# MSPM0L222X register map
Vendor: Texas Instruments; File version: This preliminary header file does not have a version number - build date: 2024-04-29 20:57:13
ARM Device
CPU: CM0 r0p1, little endian, MPU, no FPU, 3 interrupt priority bits
Registers are 32-bit, read-write, reset 0x0 unless marked. A register's access mark holds for its fields unless they carry their own. Offsets are from the block's base; lines under a group give offsets from that group; [hi:lo] are bit positions; {n}, {i} and the like mark numbered series; 'fields as' and 'values as' point back to an identical list; <NAME> marks a mode.

## Memory map
0x00000000 FLASH size 0x40000 — MEM
0x20000000 SYSMEM size 0x8000 — MEM
0x40080000 WWDT0 size 0x1500 — WWDT
0x400A0000 GPIOA size 0x1F00 — PERIPHERALREGION
0x400A2000 GPIOB size 0x1F00 — PERIPHERALREGION
0x400A4000 GPIOC size 0x1F00 — PERIPHERALREGION
0x400AC000 KEYSTORECTL size 0x2000 — PERIPHERALREGION
0x400AF000 SYSCTL size 0x3100 — mem_map
0x400C7000 DEBUGSS size 0x1F00 — DSSM
0x400C9000 EVENTLP size 0x3000 — PERIPHERALREGION
0x400CD000 FLASHCTL size 0x2000 — NVMNW_GANDALF
0x400F0000 I2C0 size 0x1F00 — PERIPHERALREGION
0x400F2000 I2C1 size 0x1F00 — PERIPHERALREGION
0x400F4000 I2C2 size 0x1F00 — PERIPHERALREGION
0x40108000 UART0 size 0x1F00 — PERIPHERALREGION
0x4010A000 UART1 size 0x1F00 — PERIPHERALREGION
0x40400000 CPUSS size 0x1F00 — CPUSSMMR
0x40428000 IOMUX size 0x2000 — PERIPHERALREGION
0x4042A000 DMA size 0x1F00 — PERIPHERALREGION
0x40440000 CRCP0 size 0x2000 — PERIPHERALREGION
0x40442000 AESADV size 0x1200 — PERIPHERALREGION
0x40444000 TRNG size 0x1E00 — PERIPHERALREGION
0x40468000 SPI0 size 0x1F00 — PERIPHERALREGION
0x41C40000 FACTORYREGION size 0x80

## Interrupts
0 INT_GROUP0 (DEBUGSS, WWDT0, FLASHCTL, SYSCTL) — DEBUGSS interrupt (group 0, IIDX 2)
1 INT_GROUP1 (GPIOA, TRNG, GPIOB, GPIOC) — GPIOA interrupt (group 1, IIDX 0)
15 UART0
16 UART1
28 AESADV
31 DMA0 (DMA)

## FACTORYREGION
Base 0x41C40000
0x00 TRACEID ro — Unique value per device shipped
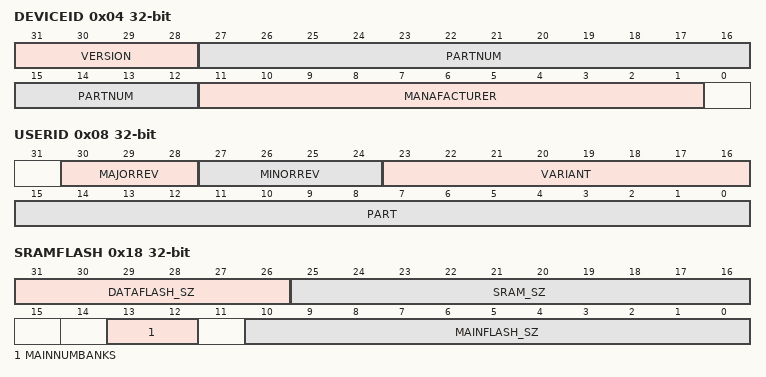
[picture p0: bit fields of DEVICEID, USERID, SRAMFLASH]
0x04 DEVICEID ro — Device Identifier
  [31:28] VERSION — Revision of this device
  [27:12] PARTNUM — Part number of the device
  [11:1] MANAFACTURER — TI's JEDEC bank and company code
0x08 USERID ro
  [30:28] MAJORREV — Monotonic increasing value indiciating a new revision of the SKU significant enough that users of the device may have tro revise PCB or software design
  [27:24] MINORREV — Monotonic increasing value indicating a new revision of the SKU that preserves compatability with lesser minor rev values. New capability may be introduced such that lesser minor rev numbers may not be compatible with greater if the new capability is used.
  [23:16] VARIANT — Bit pattern uniquely identifying the variant for the part
  [15:0] PART — Bit pattern that uniquely identifying a part
0x18 SRAMFLASH ro
  [31:26] DATAFLASH_SZ — The encoding of the field is that the value of the field is an integer to be interpreted as number of KB. For example id 4, then it is 4KB, if the value is 32, then 32KB, and so on.
  [25:16] SRAM_SZ — The encoding of the field is that the value of the field is an integer to be interpreted as number of KB. For example id 4, then it is 4KB, if the value is 32, then 32KB, and so on.
  [13:12] MAINNUMBANKS
  [10:0] MAINFLASH_SZ — The encoding of the field is that value of the field is an interger to be interpreted as number of KB. For example, if the value of the field id 4, then it is 4KB, the value is 32KB, and so on.

## Licence text in the file
Copyright (C) 2024 Texas Instruments Incorporated - http://www.ti.com/ Redistribution and use in source and binary forms, with or without modification, are permitted provided that the following conditions are met: Redistributions of source code must retain the above copyright notice, this list of conditions and the following disclaimer. Redistributions in binary form must reproduce the above copyright notice, this list of conditions and the following disclaimer in the documentation and/or other materials provided with the distribution. Neither the name of Texas Instruments Incorporated nor the names of its contributors may be used to endorse or promote products derived from this software without specific prior written permission. THIS SOFTWARE IS PROVIDED BY THE COPYRIGHT HOLDERS AND CONTRIBUTORS "AS IS" AND ANY EXPRESS OR IMPLIED WARRANTIES, INCLUDING, BUT NOT LIMITED TO, THE IMPLIED WARRANTIES OF MERCHANTABILITY AND FITNESS FOR A PARTICULAR PURPOSE ARE DISCLAIMED. IN NO EVENT SHALL THE COPYRIGHT OWNER OR CONTRIBUTORS BE LIABLE FOR ANY DIRECT, INDIRECT, INCIDENTAL, SPECIAL, EXEMPLARY, OR CONSEQUENTIAL DAMAGES (INCLUDING, BUT NOT LIMITED TO, PROCUREMENT OF SUBSTITUTE GOODS OR SERVICES; LOSS OF USE, DATA, OR PROFITS; OR BUSINESS INTERRUPTION) HOWEVER CAUSED AND ON ANY THEORY OF LIABILITY, WHETHER IN CONTRACT, STRICT LIABILITY, OR TORT (INCLUDING NEGLIGENCE OR OTHERWISE) ARISING IN ANY WAY OUT OF THE USE OF THIS SOFTWARE, EVEN IF ADVISED OF THE POSSIBILITY OF SUCH DAMAGE.
